VERSION ""

NS_ :

BS_:

BU_: XXX

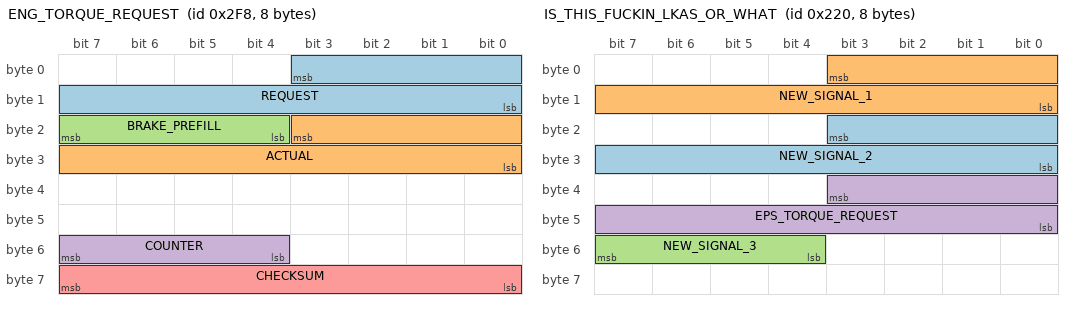
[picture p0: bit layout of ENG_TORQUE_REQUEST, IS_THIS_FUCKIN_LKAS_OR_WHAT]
BO_ 760 ENG_TORQUE_REQUEST: 8 XXX
 SG_ REQUEST : 3|12@0+ (0.5,-1024) [0|1] "" XXX
 SG_ ACTUAL : 19|12@0+ (0.5,-1024) [0|1] "" XXX
 SG_ BRAKE_PREFILL : 23|4@0+ (1,0) [0|15] "" XXX
 SG_ COUNTER : 55|4@0+ (1,0) [0|1] "" XXX
 SG_ CHECKSUM : 63|8@0+ (1,0) [0|1] "" XXX

BO_ 761 BRAKE_ASSIST: 8 XXX
 SG_ ASSIST_ACTIVE : 3|12@0+ (-0.25,1024) [0|1] "" XXX

BO_ 544 IS_THIS_FUCKIN_LKAS_OR_WHAT: 8 XXX
 SG_ NEW_SIGNAL_2 : 19|12@0+ (0.5,-1000.5) [0|1] "" XXX
 SG_ NEW_SIGNAL_1 : 3|12@0+ (1,-1024) [0|1] "" XXX
 SG_ NEW_SIGNAL_3 : 55|4@0+ (1,0) [0|1] "" XXX
 SG_ EPS_TORQUE_REQUEST : 35|12@0+ (1,0) [0|1] "" XXX

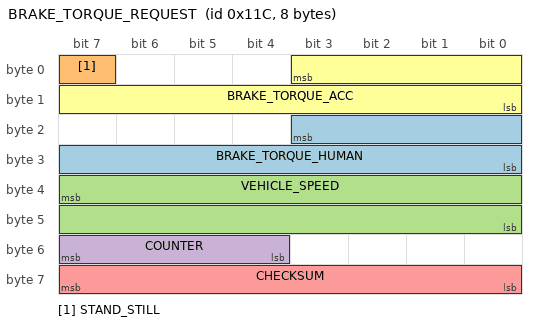
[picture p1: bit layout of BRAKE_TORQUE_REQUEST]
BO_ 284 BRAKE_TORQUE_REQUEST: 8 XXX
 SG_ BRAKE_TORQUE_HUMAN : 19|12@0+ (1,0) [0|1] "" XXX
 SG_ STAND_STILL : 7|1@0+ (1,0) [0|1] "" XXX
 SG_ VEHICLE_SPEED : 39|16@0+ (0.0025,0) [0|1] "m/s" XXX
 SG_ COUNTER : 55|4@0+ (1,0) [0|1] "" XXX
 SG_ CHECKSUM : 63|8@0+ (1,0) [0|1] "" XXX
 SG_ BRAKE_TORQUE_ACC : 3|12@0+ (1,0) [0|4095] "" XXX

BO_ 268 ACC_10C: 8 XXX
 SG_ ACC_ENG_TRQ_REQ : 3|12@0+ (0.25,-512) [0|1] "" XXX
 SG_ ACC_ENG_TRQ_ACTUAL : 19|12@0+ (0.25,-512) [0|1] "" XXX

CM_ SG_ 760 BRAKE_PREFILL "4 = ACC, 8 = HUMAN";
